# AT90PWM81 device description
Architecture: AVR8; Family: megaAVR
Registers are 8-bit, access not given, no defined reset value unless marked. A register's access mark holds for its fields unless they carry their own. Offsets are from the block's base; [hi:lo] are bit positions.

## EEPROM
Instances: EEPROM 0x00
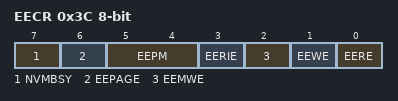
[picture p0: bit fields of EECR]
0x3C EECR — EEPROM Control Register
  [7] NVMBSY — None Volatile Busy Memory Busy
  [6] EEPAGE — EEPROM Page Access
  [5:4] EEPM — EEPROM Programming Mode
  [3] EERIE — EEPROM Ready Interrupt Enable
  [2] EEMWE — EEPROM Master Write Enable
  [1] EEWE — EEPROM Write Enable
  [0] EERE — EEPROM Read Enable
0x3D EEDR — EEPROM Data Register
  [7:0] EEDR — EEPROM Data bits
0x3E EEAR 16-bit — EEPROM Read/Write Access Bytes
  [8:0] EEAR — EEPROM Address bytes

## PSC0 — Power Stage Controller
Instances: PSC0 0x00
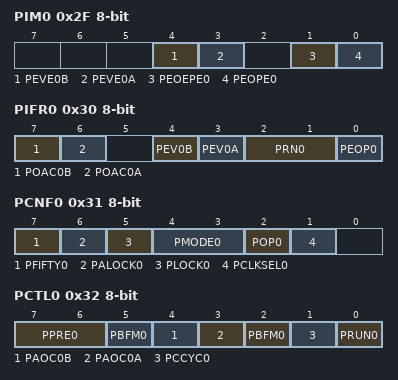
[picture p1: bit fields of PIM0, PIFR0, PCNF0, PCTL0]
0x2F PIM0 — PSC0 Interrupt Mask Register
  [4] PEVE0B — External Event B Interrupt Enable
  [3] PEVE0A — External Event A Interrupt Enable
  [1] PEOEPE0 — End of Enhanced Cycle Enable
  [0] PEOPE0 — End of Cycle Interrupt Enable
0x30 PIFR0 — PSC0 Interrupt Flag Register
  [7] POAC0B — PSC 0 Output A Activity
  [6] POAC0A — PSC 0 Output A Activity
  [4] PEV0B — External Event B Interrupt
  [3] PEV0A — External Event A Interrupt
  [2:1] PRN0 — Ramp Number
  [0] PEOP0 — End of PSC0 Interrupt
0x31 PCNF0 — PSC 0 Configuration Register
  [7] PFIFTY0 — PSC 0 Fifty
  [6] PALOCK0 — PSC 0 Autolock
  [5] PLOCK0 — PSC 0 Lock
  [4:3] PMODE0 — PSC 0 Mode
  [2] POP0 — PSC 0 Output Polarity
  [1] PCLKSEL0 — PSC 0 Input Clock Select
0x32 PCTL0 — PSC 0 Control Register
  [7:6] PPRE0 — PSC 0 Prescaler Selects
  [4] PAOC0B — PSC 0 Asynchronous Output Control B
  [3] PAOC0A — PSC 0 Asynchronous Output Control A
  [5,2] PBFM0 — PSC 0 Balance Flank Width Modulation
  [1] PCCYC0 — PSC0 Complete Cycle
  [0] PRUN0 — PSC 0 Run
0x42 OCR0SB 16-bit — Output Compare SB Register
  [11:0] OCR0SB — Output Compare 0 SB
0x44 OCR0RB 16-bit — Output Compare RB Register
  [15:0] OCR0RB — Output Compare 0 RB
0x4A OCR0RA 16-bit — Output Compare RA Register
  [11:0] OCR0RA — Output Compare 0 RA
0x60 OCR0SA 16-bit — Output Compare SA Register
  [11:0] OCR0SA — Output Compare 0 SA
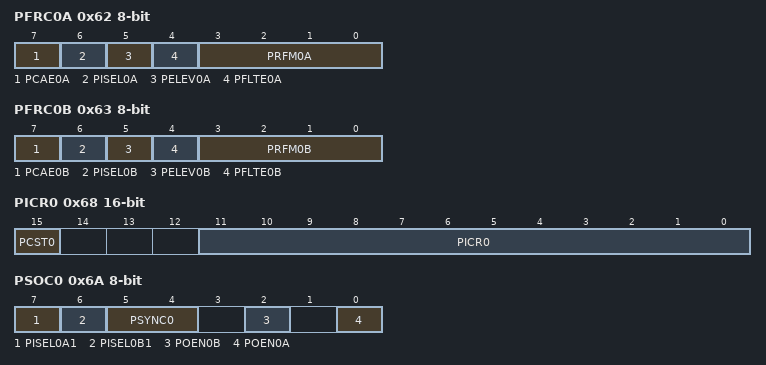
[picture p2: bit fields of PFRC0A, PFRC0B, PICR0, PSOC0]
0x62 PFRC0A — PSC 0 Input A Control
  [7] PCAE0A — PSC 0 Capture Enable Input Part A
  [6] PISEL0A — PSC 0 Input Select for Part A
  [5] PELEV0A — PSC 0 Edge Level Selector on Input Part A
  [4] PFLTE0A — PSC 0 Filter Enable on Input Part A
  [3:0] PRFM0A — PSC 0 Retrigger and Fault Mode for Part A
0x63 PFRC0B — PSC 0 Input B Control
  [7] PCAE0B — PSC 0 Capture Enable Input Part B
  [6] PISEL0B — PSC 0 Input Select for Part B
  [5] PELEV0B — PSC 0 Edge Level Selector on Input Part B
  [4] PFLTE0B — PSC 0 Filter Enable on Input Part B
  [3:0] PRFM0B — PSC 0 Retrigger and Fault Mode for Part B
0x68 PICR0 16-bit — PSC 0 Input Capture Register
  [15] PCST0 — PSC 0 Capture Software Trigger Bit
  [11:0] PICR0 — PSC 0 Input Capture Bytes
0x6A PSOC0 — PSC0 Synchro and Output Configuration
  [7] PISEL0A1 — PSC Input Select
  [6] PISEL0B1 — PSC Input Select
  [5:4] PSYNC0 — Synchronisation out for ADC selection
  [2] POEN0B — PSCOUT01 Output Enable
  [0] POEN0A — PSCOUT00 Output Enable

## PSC2 — Power Stage Controller
Instances: PSC2 0x00
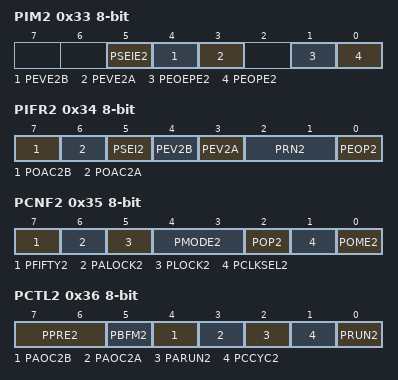
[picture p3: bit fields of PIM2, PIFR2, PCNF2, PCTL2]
0x33 PIM2 — PSC2 Interrupt Mask Register
  [5] PSEIE2 — PSC 2 Synchro Error Interrupt Enable
  [4] PEVE2B — External Event B Interrupt Enable
  [3] PEVE2A — External Event A Interrupt Enable
  [1] PEOEPE2 — End of Enhanced Cycle Interrupt Enable
  [0] PEOPE2 — End of Cycle Interrupt Enable
0x34 PIFR2 — PSC2 Interrupt Flag Register
  [7] POAC2B — PSC 2 Output A Activity
  [6] POAC2A — PSC 2 Output A Activity
  [5] PSEI2 — PSC 2 Synchro Error Interrupt
  [4] PEV2B — External Event B Interrupt
  [3] PEV2A — External Event A Interrupt
  [2:1] PRN2 — Ramp Number
  [0] PEOP2 — End of PSC2 Interrupt
0x35 PCNF2 — PSC 2 Configuration Register
  [7] PFIFTY2 — PSC 2 Fifty
  [6] PALOCK2 — PSC 2 Autolock
  [5] PLOCK2 — PSC 2 Lock
  [4:3] PMODE2 — PSC 2 Mode
  [2] POP2 — PSC 2 Output Polarity
  [1] PCLKSEL2 — PSC 2 Input Clock Select
  [0] POME2 — PSC 2 Output Matrix Enable
0x36 PCTL2 — PSC 2 Control Register
  [7:6] PPRE2 — PSC 2 Prescaler Selects
  [5] PBFM2 — Balance Flank Width Modulation
  [4] PAOC2B — PSC 2 Asynchronous Output Control B
  [3] PAOC2A — PSC 2 Asynchronous Output Control A
  [2] PARUN2 — PSC2 Auto Run
  [1] PCCYC2 — PSC2 Complete Cycle
  [0] PRUN2 — PSC 2 Run
0x46 OCR2SB 16-bit — Output Compare SB Register
  [11:0] OCR2SB — Output Compare 2 SB
0x48 OCR2RB 16-bit — Output Compare RB Register
  [15:0] OCR2RB — Output Compare 2 RB
0x4E OCR2RA 16-bit — Output Compare RA Register
  [11:0] OCR2RA — Output Compare 2 RA
0x64 OCR2SA 16-bit — Output Compare SA Register
  [11:0] OCR2SA — Output Compare 2 SA
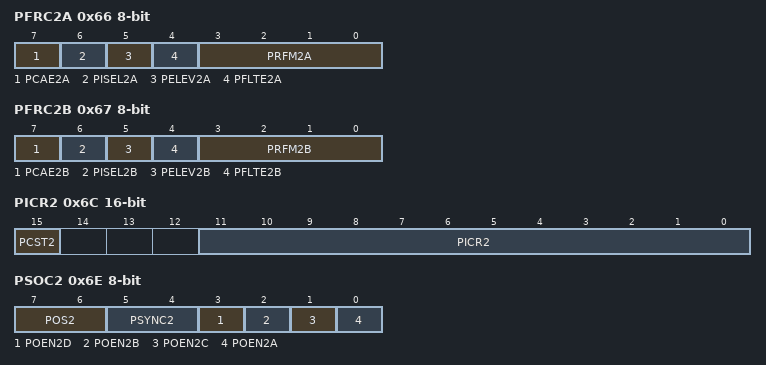
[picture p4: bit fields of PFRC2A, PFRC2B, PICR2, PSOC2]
0x66 PFRC2A — PSC 2 Input B Control
  [7] PCAE2A — PSC 2 Capture Enable Input Part A
  [6] PISEL2A — PSC 2 Input Select for Part A
  [5] PELEV2A — PSC 2 Edge Level Selector on Input Part A
  [4] PFLTE2A — PSC 2 Filter Enable on Input Part A
  [3:0] PRFM2A — PSC 2 Retrigger and Fault Mode for Part A
0x67 PFRC2B — PSC 2 Input B Control
  [7] PCAE2B — PSC 2 Capture Enable Input Part B
  [6] PISEL2B — PSC 2 Input Select for Part B
  [5] PELEV2B — PSC 2 Edge Level Selector on Input Part B
  [4] PFLTE2B — PSC 2 Filter Enable on Input Part B
  [3:0] PRFM2B — PSC 2 Retrigger and Fault Mode for Part B
0x6C PICR2 16-bit — PSC 2 Input Capture Register
  [15] PCST2 — PSC 2 Capture Software Trigger Bit
  [11:0] PICR2 — PSC 2 Input Capture Bytes
0x6E PSOC2 — PSC2 Synchro and Output Configuration
  [7:6] POS2 (bit 2 of the value upward) — PSC 2 Output 23 Select
  [5:4] PSYNC2 — Synchronization Out for ADC Selection
  [3] POEN2D — PSCOUT23 Output Enable
  [2] POEN2B — PSCOUT21 Output Enable
  [1] POEN2C — PSCOUT22 Output Enable
  [0] POEN2A — PSCOUT20 Output Enable
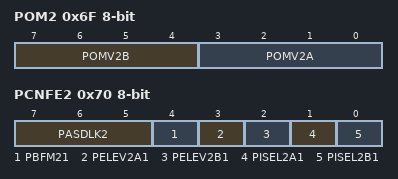
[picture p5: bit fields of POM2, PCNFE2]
0x6F POM2 — PSC 2 Output Matrix
  [7:4] POMV2B — Output Matrix Output B Ramps
  [3:0] POMV2A — Output Matrix Output A Ramps
0x70 PCNFE2 — PSC 2 Enhanced Configuration Register
  [7:5] PASDLK2, [4] PBFM21, [3] PELEV2A1, [2] PELEV2B1, [1] PISEL2A1, [0] PISEL2B1
0x71 PASDLY2 — Analog Synchronization Delay Register
  [7:0] PASDLY2 — Analog Synchronization Delay bits

## TC1 (TC16 module) — Timer/Counter, 16-bit
Instances: TC1 0x00
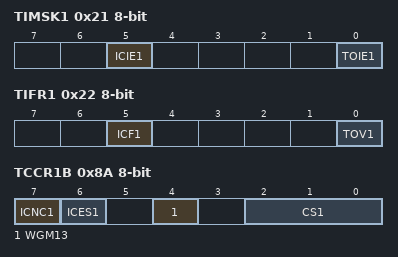
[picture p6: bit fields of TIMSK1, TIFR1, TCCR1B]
0x21 TIMSK1 — Timer/Counter Interrupt Mask Register
  [5] ICIE1 — Timer/Counter1 Input Capture Interrupt Enable
  [0] TOIE1 — Timer/Counter1 Overflow Interrupt Enable
0x22 TIFR1 — Timer/Counter Interrupt Flag register
  [5] ICF1 — Input Capture Flag 1
  [0] TOV1 — Timer/Counter1 Overflow Flag
0x5A TCNT1 16-bit — Timer/Counter1 Bytes
  [15:0] TCNT1 — Timer/Counter 1 bits
0x8A TCCR1B — Timer/Counter1 Control Register B
  [7] ICNC1 — Input Capture 1 Noise Canceler
  [6] ICES1 — Input Capture 1 Edge Select
  [4] WGM13 — Waveform Generation Mode
  [2:0] CS1 — Prescaler source of Timer/Counter 1
    0=No Clock Source (Stopped); 1=Running, No Prescaling; 2=Running, CLK/8; 3=Running, CLK/64; 4=Running, CLK/256; 5=Running, CLK/1024; 6=Running, ExtClk Tx Falling Edge; 7=Running, ExtClk Tx Rising Edge
0x8C ICR1 16-bit — Timer/Counter1 Input Capture Register Bytes
  [15:0] ICR1 — Timer/Counter1 Input Capture bits

## BOOT_LOAD — Bootloader
Instances: BOOT_LOAD 0x00
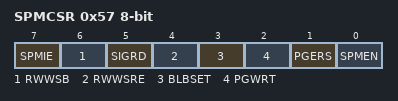
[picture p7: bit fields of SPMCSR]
0x57 SPMCSR — Store Program Memory Control Register
  [7] SPMIE — SPM Interrupt Enable
  [6] RWWSB — Read While Write Section Busy
  [5] SIGRD — Signature Row Read
  [4] RWWSRE — Read While Write section read enable
  [3] BLBSET — Boot Lock Bit Set
  [2] PGWRT — Page Write
  [1] PGERS — Page Erase
  [0] SPMEN — Store Program Memory Enable
